# HC32F558 register map
File version: 1.0
CPU: CM4 r0p1, little endian, MPU, FPU, 4 interrupt priority bits
Registers are 32-bit, read-write, reset 0x0 unless marked. A register's access mark holds for its fields unless they carry their own. Offsets are from the block's base; [hi:lo] are bit positions; {n}, {i} and the like mark numbered series.

## SDFM
Base 0x4003A800
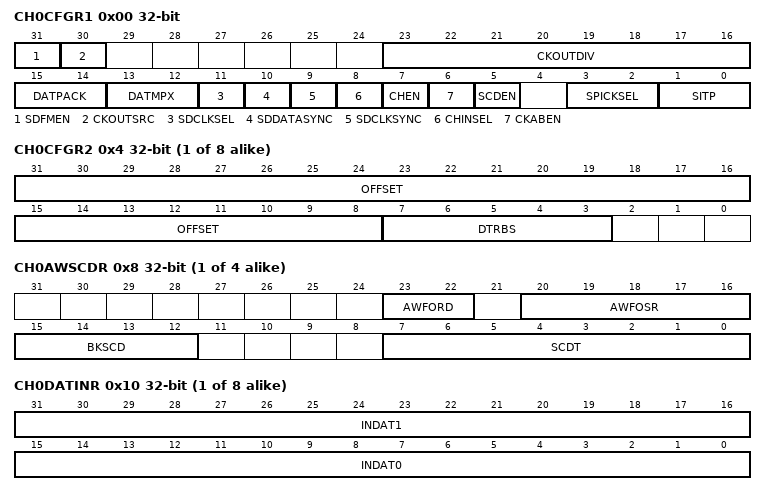
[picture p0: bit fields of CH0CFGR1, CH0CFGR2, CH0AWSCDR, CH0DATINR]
0x00 CH0CFGR1
  [31] SDFMEN, [30] CKOUTSRC, [23:16] CKOUTDIV, [15:14] DATPACK, [13:12] DATMPX, [11] SDCLKSEL, [10] SDDATASYNC, [9] SDCLKSYNC, [8] CHINSEL, [7] CHEN, [6] CKABEN, [5] SCDEN, [3:2] SPICKSEL, [1:0] SITP
{0x4+0x20*i} CH{i}CFGR2 (i=0..7)
  [31:8] OFFSET, [7:3] DTRBS
{0x8+0x20*i} CH{i}AWSCDR (i=0..3)
  [23:22] AWFORD, [20:16] AWFOSR, [15:12] BKSCD, [7:0] SCDT
{0xC+0x20*i} CH{i}WDATAR ro (i=0..7)
  [15:0] WDATR
{0x10+0x20*i} CH{i}DATINR (i=0..7)
  [31:16] INDAT1, [15:0] INDAT0
{0x14+0x20*i} CH{i}DLYR (i=0..7)
  [5:0] PSSKP
{0x18+0x20*i} CH{i}HLTZ (i=0..7)
  [15:0] HLTZ
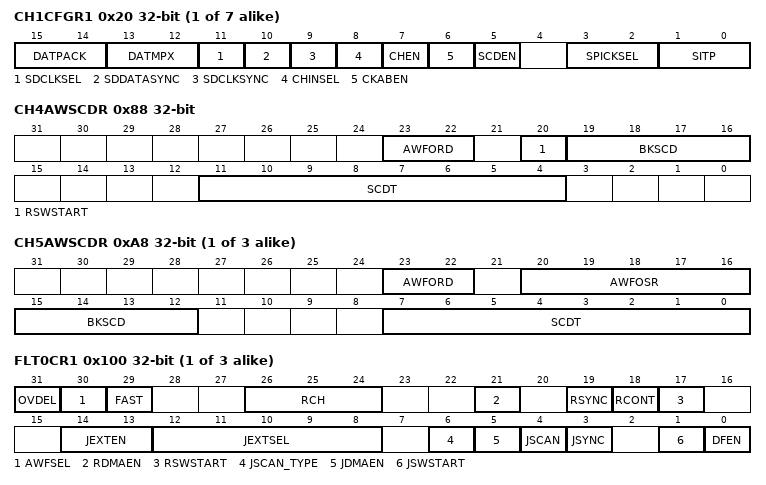
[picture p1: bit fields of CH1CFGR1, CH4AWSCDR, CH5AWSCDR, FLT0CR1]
{0x0+0x20*i} CH{i}CFGR1 (i=1..7)
  [15:14] DATPACK, [13:12] DATMPX, [11] SDCLKSEL, [10] SDDATASYNC, [9] SDCLKSYNC, [8] CHINSEL, [7] CHEN, [6] CKABEN, [5] SCDEN, [3:2] SPICKSEL, [1:0] SITP
0x88 CH4AWSCDR
  [23:22] AWFORD, [20] RSWSTART, [19:16] BKSCD, [11:4] SCDT
{0x8+0x20*i} CH{i}AWSCDR (i=5..7)
  [23:22] AWFORD, [20:16] AWFOSR, [15:12] BKSCD, [7:0] SCDT
{0x100+0x80*i} FLT{i}CR1 (i=0..2)
  [31] OVDEL, [30] AWFSEL, [29] FAST, [26:24] RCH, [21] RDMAEN, [19] RSYNC, [18] RCONT, [17] RSWSTART wo, [14:13] JEXTEN, [12:8] JEXTSEL, [6] JSCAN_TYPE, [5] JDMAEN, [4] JSCAN, [3] JSYNC, [1] JSWSTART wo, [0] DFEN
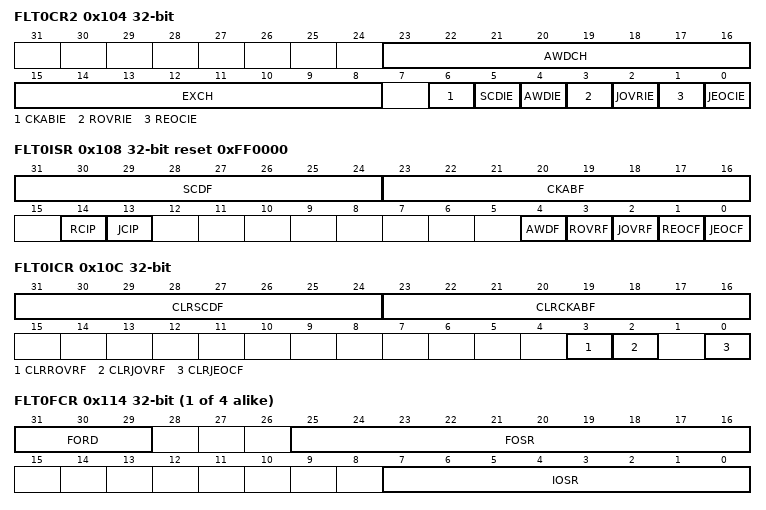
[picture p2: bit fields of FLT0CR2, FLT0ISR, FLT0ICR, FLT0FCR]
0x104 FLT0CR2
  [23:16] AWDCH, [15:8] EXCH, [6] CKABIE, [5] SCDIE, [4] AWDIE, [3] ROVRIE, [2] JOVRIE, [1] REOCIE, [0] JEOCIE
0x108 FLT0ISR ro reset 0xFF0000
  [31:24] SCDF, [23:16] CKABF, [14] RCIP, [13] JCIP, [4] AWDF, [3] ROVRF, [2] JOVRF, [1] REOCF, [0] JEOCF
0x10C FLT0ICR wo
  [31:24] CLRSCDF, [23:16] CLRCKABF, [3] CLRROVRF, [2] CLRJOVRF, [0] CLRJEOCF
{0x110+0x80*i} FLT{i}JCHGR reset 0x1 (i=0..3)
  [7:0] JCHG
{0x114+0x80*i} FLT{i}FCR (i=0..3)
  [31:29] FORD, [25:16] FOSR, [7:0] IOSR
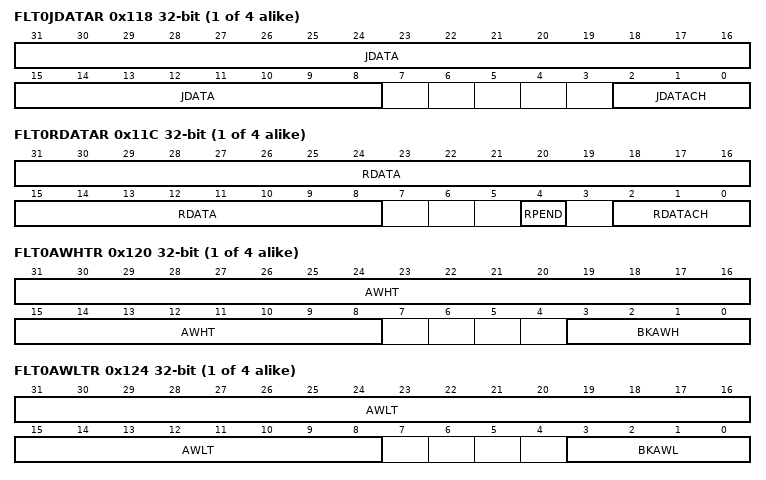
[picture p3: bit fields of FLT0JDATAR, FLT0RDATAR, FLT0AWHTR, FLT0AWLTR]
{0x118+0x80*i} FLT{i}JDATAR ro (i=0..3)
  [31:8] JDATA, [2:0] JDATACH
{0x11C+0x80*i} FLT{i}RDATAR ro (i=0..3)
  [31:8] RDATA, [4] RPEND, [2:0] RDATACH
{0x120+0x80*i} FLT{i}AWHTR (i=0..3)
  [31:8] AWHT, [3:0] BKAWH
{0x124+0x80*i} FLT{i}AWLTR (i=0..3)
  [31:8] AWLT, [3:0] BKAWL
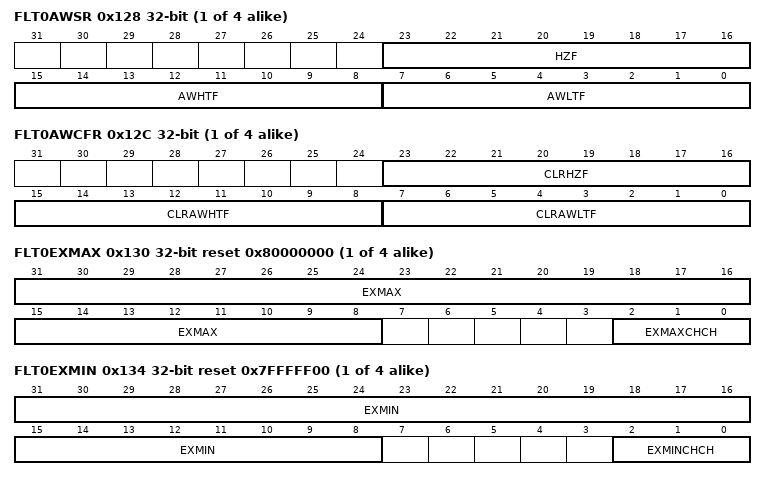
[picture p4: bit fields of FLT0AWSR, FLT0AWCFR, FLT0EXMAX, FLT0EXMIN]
{0x128+0x80*i} FLT{i}AWSR ro (i=0..3)
  [23:16] HZF, [15:8] AWHTF, [7:0] AWLTF
{0x12C+0x80*i} FLT{i}AWCFR wo (i=0..3)
  [23:16] CLRHZF, [15:8] CLRAWHTF, [7:0] CLRAWLTF
{0x130+0x80*i} FLT{i}EXMAX ro reset 0x80000000 (i=0..3)
  [31:8] EXMAX, [2:0] EXMAXCHCH
{0x134+0x80*i} FLT{i}EXMIN ro reset 0x7FFFFF00 (i=0..3)
  [31:8] EXMIN, [2:0] EXMINCHCH
{0x138+0x80*i} FLT{i}CNVTIMR ro (i=0..3)
  [31:4] CNVCNT
{0x13C+0x80*i} FLT{i}CNVTHRE reset 0x24 (i=0..3)
  [5:0] CNVTHRE
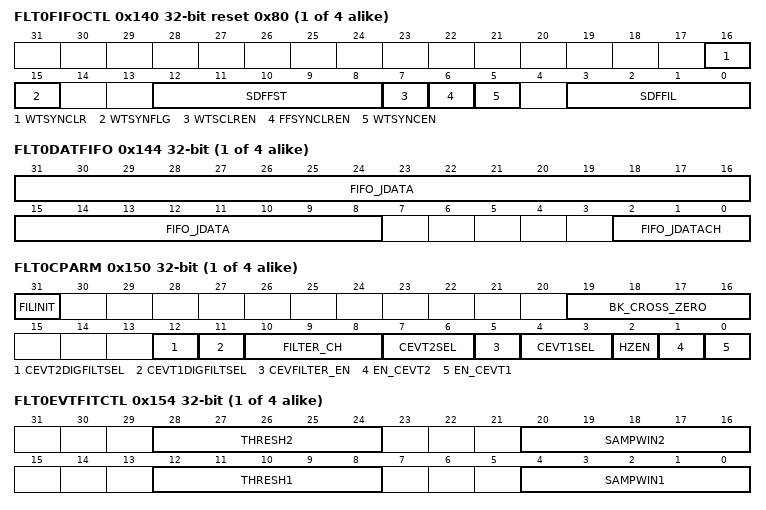
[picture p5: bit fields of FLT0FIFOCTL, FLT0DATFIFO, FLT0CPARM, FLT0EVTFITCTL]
{0x140+0x80*i} FLT{i}FIFOCTL reset 0x80 (i=0..3)
  [16] WTSYNCLR wo, [15] WTSYNFLG ro, [12:8] SDFFST ro, [7] WTSCLREN, [6] FFSYNCLREN, [5] WTSYNCEN, [3:0] SDFFIL
{0x144+0x80*i} FLT{i}DATFIFO ro (i=0..3)
  [31:8] FIFO_JDATA, [2:0] FIFO_JDATACH
{0x148+0x80*i} FLT{i}AWHT2 (i=0..3)
  [31:16] AWHT2
{0x14C+0x80*i} FLT{i}AWLT2 (i=0..3)
  [31:16] AWLT2
{0x150+0x80*i} FLT{i}CPARM (i=0..3)
  [31] FILINIT wo, [19:16] BK_CROSS_ZERO, [12] CEVT2DIGFILTSEL, [11] CEVT1DIGFILTSEL, [10:8] FILTER_CH, [7:6] CEVT2SEL, [5] CEVFILTER_EN, [4:3] CEVT1SEL, [2] HZEN, [1] EN_CEVT2, [0] EN_CEVT1
{0x154+0x80*i} FLT{i}EVTFITCTL (i=0..3)
  [28:24] THRESH2, [20:16] SAMPWIN2, [12:8] THRESH1, [4:0] SAMPWIN1
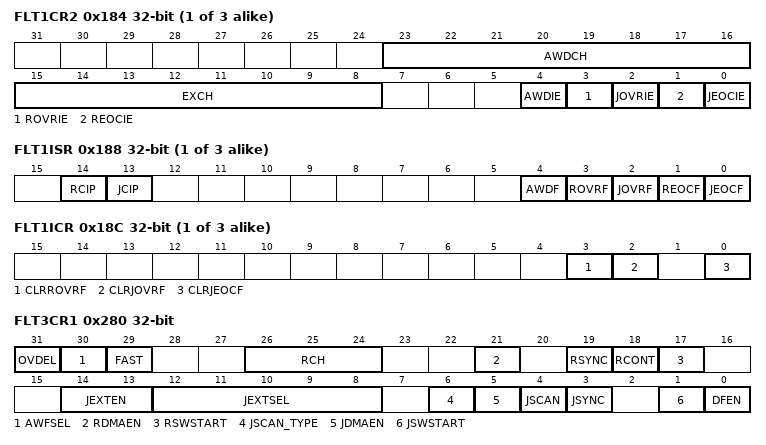
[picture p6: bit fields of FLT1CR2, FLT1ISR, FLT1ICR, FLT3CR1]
{0x104+0x80*i} FLT{i}CR2 (i=1..3)
  [23:16] AWDCH, [15:8] EXCH, [4] AWDIE, [3] ROVRIE, [2] JOVRIE, [1] REOCIE, [0] JEOCIE
{0x108+0x80*i} FLT{i}ISR ro (i=1..3)
  [14] RCIP, [13] JCIP, [4] AWDF, [3] ROVRF, [2] JOVRF, [1] REOCF, [0] JEOCF
{0x10C+0x80*i} FLT{i}ICR wo (i=1..3)
  [3] CLRROVRF, [2] CLRJOVRF, [0] CLRJEOCF
0x280 FLT3CR1
  [31] OVDEL, [30] AWFSEL, [29] FAST, [26:24] RCH, [21] RDMAEN, [19] RSYNC, [18] RCONT, [17] RSWSTART, [14:13] JEXTEN, [12:8] JEXTSEL, [6] JSCAN_TYPE, [5] JDMAEN, [4] JSCAN, [3] JSYNC, [1] JSWSTART wo, [0] DFEN
